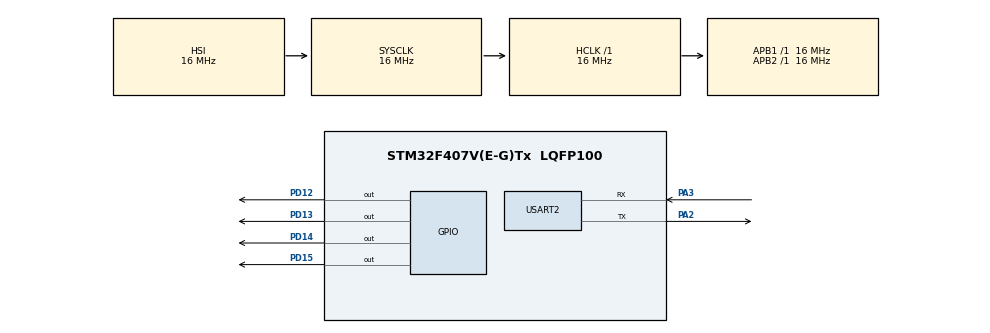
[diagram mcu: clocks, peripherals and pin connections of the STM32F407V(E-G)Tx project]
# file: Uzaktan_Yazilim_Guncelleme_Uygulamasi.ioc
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Mcu.Family=STM32F4
Mcu.Name=STM32F407V(E-G)Tx
Mcu.Package=LQFP100
NVIC.PriorityGroup=NVIC_PRIORITYGROUP_4
NVIC.TIM3_IRQn=true\:0\:0\:false\:false\:true\:true\:true
NVIC.USART2_IRQn=true\:0\:0\:false\:false\:true\:true\:true
PA13.Mode=Serial_Wire
PA13.Signal=SYS_JTMS-SWDIO
PA14.Mode=Serial_Wire
PA14.Signal=SYS_JTCK-SWCLK
PA2.Mode=Asynchronous
PA2.Signal=USART2_TX
PA3.Mode=Asynchronous
PA3.Signal=USART2_RX
PD12.Signal=GPIO_Output
PD13.Signal=GPIO_Output
PD14.Signal=GPIO_Output
PD15.Signal=GPIO_Output
ProjectManager.HeapSize=0x200
ProjectManager.StackSize=0x400
ProjectManager.TargetToolchain=STM32CubeIDE
RCC.AHBFreq_Value=16000000
RCC.APB1Freq_Value=16000000
RCC.APB2Freq_Value=16000000
RCC.CortexFreq_Value=16000000
RCC.HSE_VALUE=25000000
RCC.HSI_VALUE=16000000
RCC.LSE_VALUE=32768
RCC.SYSCLKFreq_VALUE=16000000
RCC.VCOOutputFreq_Value=192000000
TIM3.Period=10000
TIM3.Prescaler=16000
USART2.VirtualMode=VM_ASYNC
VP_TIM3_VS_ClockSourceINT.Mode=Internal
board=custom

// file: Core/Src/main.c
/* USER CODE BEGIN Header */
/**
  ******************************************************************************
  * @file           : main.c
  * @brief          : Main program body
  ******************************************************************************
  * @attention
  *
  * <h2><center>&copy; Copyright (c) 2020 STMicroelectronics.
  * All rights reserved.</center></h2>
  *
  * This software component is licensed by ST under BSD 3-Clause license,
  * the "License"; You may not use this file except in compliance with the
  * License. You may obtain a copy of the License at:
  *                        opensource.org/licenses/BSD-3-Clause
  *
  ******************************************************************************
  */
/* USER CODE END Header */

#include "main.h"

TIM_HandleTypeDef htim3;

UART_HandleTypeDef huart2;

void SystemClock_Config(void);
static void MX_GPIO_Init(void);
static void MX_TIM3_Init(void);
static void MX_USART2_UART_Init(void);

int main(void)
{

  /* MCU Configuration--------------------------------------------------------*/

  /* Reset of all peripherals, Initializes the Flash interface and the Systick. */
  HAL_Init();

  /* Configure the system clock */
  SystemClock_Config();

  /* Initialize all configured peripherals */
  MX_GPIO_Init();
  MX_TIM3_Init();
  MX_USART2_UART_Init();
  /* USER CODE BEGIN 2 */

  initial_arrangement();

  /* USER CODE END 2 */

  /* Infinite loop */
  while (1)
  {

    /* USER CODE BEGIN 3 */
	  FOTA_main();

  }
  /* USER CODE END 3 */
}

void SystemClock_Config(void)
{
  RCC_OscInitTypeDef RCC_OscInitStruct = {0};
  RCC_ClkInitTypeDef RCC_ClkInitStruct = {0};

  /** Configure the main internal regulator output voltage
  */
  __HAL_RCC_PWR_CLK_ENABLE();
  __HAL_PWR_VOLTAGESCALING_CONFIG(PWR_REGULATOR_VOLTAGE_SCALE1);
  /** Initializes the CPU, AHB and APB busses clocks
  */
  RCC_OscInitStruct.OscillatorType = RCC_OSCILLATORTYPE_HSI;
  RCC_OscInitStruct.HSIState = RCC_HSI_ON;
  RCC_OscInitStruct.HSICalibrationValue = RCC_HSICALIBRATION_DEFAULT;
  RCC_OscInitStruct.PLL.PLLState = RCC_PLL_NONE;
  if (HAL_RCC_OscConfig(&RCC_OscInitStruct) != HAL_OK)
  {
    Error_Handler();
  }
  /** Initializes the CPU, AHB and APB busses clocks
  */
  RCC_ClkInitStruct.ClockType = RCC_CLOCKTYPE_HCLK|RCC_CLOCKTYPE_SYSCLK
                              |RCC_CLOCKTYPE_PCLK1|RCC_CLOCKTYPE_PCLK2;
  RCC_ClkInitStruct.SYSCLKSource = RCC_SYSCLKSOURCE_HSI;
  RCC_ClkInitStruct.AHBCLKDivider = RCC_SYSCLK_DIV1;
  RCC_ClkInitStruct.APB1CLKDivider = RCC_HCLK_DIV1;
  RCC_ClkInitStruct.APB2CLKDivider = RCC_HCLK_DIV1;

  if (HAL_RCC_ClockConfig(&RCC_ClkInitStruct, FLASH_LATENCY_0) != HAL_OK)
  {
    Error_Handler();
  }
}

static void MX_TIM3_Init(void)
{

  TIM_ClockConfigTypeDef sClockSourceConfig = {0};
  TIM_MasterConfigTypeDef sMasterConfig = {0};

  htim3.Instance = TIM3;
  htim3.Init.Prescaler = 16000;
  htim3.Init.CounterMode = TIM_COUNTERMODE_UP;
  htim3.Init.Period = 10000;
  htim3.Init.ClockDivision = TIM_CLOCKDIVISION_DIV1;
  htim3.Init.AutoReloadPreload = TIM_AUTORELOAD_PRELOAD_DISABLE;
  if (HAL_TIM_Base_Init(&htim3) != HAL_OK)
  {
    Error_Handler();
  }
  sClockSourceConfig.ClockSource = TIM_CLOCKSOURCE_INTERNAL;
  if (HAL_TIM_ConfigClockSource(&htim3, &sClockSourceConfig) != HAL_OK)
  {
    Error_Handler();
  }
  sMasterConfig.MasterOutputTrigger = TIM_TRGO_RESET;
  sMasterConfig.MasterSlaveMode = TIM_MASTERSLAVEMODE_DISABLE;
  if (HAL_TIMEx_MasterConfigSynchronization(&htim3, &sMasterConfig) != HAL_OK)
  {
    Error_Handler();
  }

}

static void MX_USART2_UART_Init(void)
{

  huart2.Instance = USART2;
  huart2.Init.BaudRate = 115200;
  huart2.Init.WordLength = UART_WORDLENGTH_8B;
  huart2.Init.StopBits = UART_STOPBITS_1;
  huart2.Init.Parity = UART_PARITY_NONE;
  huart2.Init.Mode = UART_MODE_TX_RX;
  huart2.Init.HwFlowCtl = UART_HWCONTROL_NONE;
  huart2.Init.OverSampling = UART_OVERSAMPLING_16;
  if (HAL_UART_Init(&huart2) != HAL_OK)
  {
    Error_Handler();
  }

}

static void MX_GPIO_Init(void)
{
  GPIO_InitTypeDef GPIO_InitStruct = {0};

  /* GPIO Ports Clock Enable */
  __HAL_RCC_GPIOA_CLK_ENABLE();
  __HAL_RCC_GPIOD_CLK_ENABLE();

  /*Configure GPIO pin Output Level */
  HAL_GPIO_WritePin(GPIOD, GPIO_PIN_12|GPIO_PIN_13|GPIO_PIN_14|GPIO_PIN_15, GPIO_PIN_RESET);

  /*Configure GPIO pins : PD12 PD13 PD14 PD15 */
  GPIO_InitStruct.Pin = GPIO_PIN_12|GPIO_PIN_13|GPIO_PIN_14|GPIO_PIN_15;
  GPIO_InitStruct.Mode = GPIO_MODE_OUTPUT_PP;
  GPIO_InitStruct.Pull = GPIO_NOPULL;
  GPIO_InitStruct.Speed = GPIO_SPEED_FREQ_LOW;
  HAL_GPIO_Init(GPIOD, &GPIO_InitStruct);

}

/* USER CODE BEGIN 4 */
void HAL_TIM_PeriodElapsedCallback(TIM_HandleTypeDef *htim)
{
	uint32_t veri_sector3_adres0 = *(uint32_t*)0x0800C000 ;

	if( (ESP_datas.connection_status_with_server == OFF) &&
		(veri_sector3_adres0 != 0xFFFFFFFF )                )//VERİ VAR server kapalı
	{
		HAL_GPIO_TogglePin(GPIOD, GPIO_PIN_12);

		FOTA.State_of_FOTA = EXECUTE_THE_NEW_FIRMWARE;
	}
}

void HAL_UART_RxCpltCallback(UART_HandleTypeDef *huart)
{
	if (huart->Instance == USART2)
	{
		RX_Callback();
	}
}

/* USER CODE END 4 */

void Error_Handler(void)
{
}

/************************ (C) COPYRIGHT STMicroelectronics *****END OF FILE****/
